# MKS22F12 register map
Vendor: Freescale Semiconductor, Inc.; Series: Kinetis_K; File version: 1.6
CPU: CM4 r0p1, little endian, no MPU, FPU, VTOR, 4 interrupt priority bits
Registers are 32-bit, read-write, reset 0x0 unless marked. A register's access mark holds for its fields unless they carry their own. Offsets are from the block's base; [hi:lo] are bit positions; {n}, {i} and the like mark numbered series; 'fields as' and 'values as' point back to an identical list.

## SIM — System Integration Module
Base 0x40047000; register names take the prefix SIM_
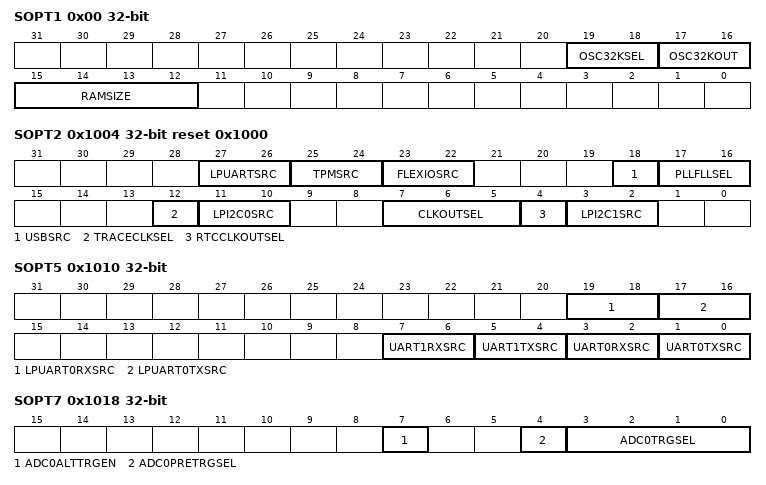
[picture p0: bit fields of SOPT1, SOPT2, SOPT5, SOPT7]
0x00 SOPT1 (reset mask 0x1FFF0FC0) — System Options Register 1
  [19:18] OSC32KSEL — 32K oscillator clock select
    0=System oscillator (OSC32KCLK); 2=RTC 32.768kHz oscillator; 3=LPO 1 kHz
  [17:16] OSC32KOUT — 32K Oscillator Clock Output
    0=ERCLK32K is not output; 1=ERCLK32K is output on PTE0; 2=ERCLK32K is output on PTE26
  [15:12] RAMSIZE ro
    1=8 KB; 3=16 KB; 4=24 KB; 5=32 KB; 6=48 KB; 7=64 KB; 8=96 KB; 9=128 KB; 11=256 KB
0x1004 SOPT2 reset 0x1000 — System Options Register 2
  [27:26] LPUARTSRC — LPUART clock source select
    0=Clock disabled; 1=MCGFLLCLK , or MCGPLLCLK , or IRC48M clock as selected by SOPT2[PLLFLLSEL]; 2=OSCERCLK clock; 3=MCGIRCLK clock
  [25:24] TPMSRC — TPM clock source select
    values as LPUARTSRC
  [23:22] FLEXIOSRC — FlexIO Module Clock Source Select
    0=I2S0_MCLK or System clock, selected via SIM_MISCCTRL[FlEXIOS0]; 1=MCGFLLCLK , or MCGPLLCLK , or IRC48M clock as selected by SOPT2[PLLFLLSEL]; 2=OSCERCLK clock; 3=MCGIRCLK clock
  [18] USBSRC — USB clock source select
    0=External bypass clock (USB_CLKIN); 1=MCGFLLCLK, or MCGPLLCLK , or IRC48M clock as selected by SOPT2[PLLFLLSEL], and then divided by the USB fractional divider as configured by SIM_CLKDIV2[USBFRAC, USBDIV]
  [17:16] PLLFLLSEL — PLL/FLL clock select
    0=MCGFLLCLK clock; 1=MCGPLLCLK clock; 3=IRC48 MHz clock
  [12] TRACECLKSEL — Debug trace clock select
    0=MCGOUTCLK; 1=Core/system clock
  [11:10] LPI2C0SRC — LPI2C0 source
    values as LPUARTSRC
  [7:5] CLKOUTSEL — CLKOUT select
    2=Flash clock; 3=LPO clock (1 kHz); 4=MCGIRCLK; 5=RTC 32.768kHz clock; 6=OSCERCLK0; 7=IRC 48 MHz clock
  [4] RTCCLKOUTSEL — RTC clock out select
    0=RTC 1 Hz clock is output on the RTC_CLKOUT pin; 1=RTC 32.768kHz clock is output on the RTC_CLKOUT pin
  [3:2] LPI2C1SRC — LPI2C1 source
    values as LPUARTSRC
0x1010 SOPT5 — System Options Register 5
  [19:18] LPUART0RXSRC — LPUART0 receive data source select
    0=LPUART0_RX pin; 1=CMP0 output
  [17:16] LPUART0TXSRC — LPUART0 transmit data source select
    0=LPUART0_TX pin; 1=LPUART0_TX pin modulated with TPM1 channel 0 output; 2=LPUART0_TX pin modulated with TPM2 channel 0 output
  [7:6] UART1RXSRC — UART 1 receive data source select
    0=UART1_RX pin; 1=CMP0 output
  [5:4] UART1TXSRC — UART 1 transmit data source select
    0=UART1_TX pin; 1=UART1_TX pin modulated with TPM1 channel 0 output; 2=UART1_TX pin modulated with TPM2 channel 0 output
  [3:2] UART0RXSRC — UART 0 receive data source select
    0=UART0_RX pin; 1=CMP0 output
  [1:0] UART0TXSRC — UART 0 transmit data source select
    0=UART0_TX pin; 1=UART0_TX pin modulated with TPM1 channel 0 output; 2=UART0_TX pin modulated with TPM2 channel 0 output
0x1018 SOPT7 — System Options Register 7
  [7] ADC0ALTTRGEN — ADC0 alternate trigger enable
    0=PDB trigger selected for ADC0; 1=Alternate trigger selected for ADC0
  [4] ADC0PRETRGSEL — ADC0 pretrigger select
    0=Pre-trigger A; 1=Pre-trigger B
  [3:0] ADC0TRGSEL — ADC0 trigger select
    0=PDB external trigger pin input (PDB0_EXTRG); 1=High speed comparator 0 output; {v}=PIT trigger {v-4} (v=4..7); 8=TPM0 overflow; 9=TPM1 overflow; 10=TPM2 overflow; 12=RTC alarm; 13=RTC seconds; 14=Low-power timer (LPTMR) trigger; 15=TPM1 channel 0 (A pretrigger) and channel 1 (B pretrigger)
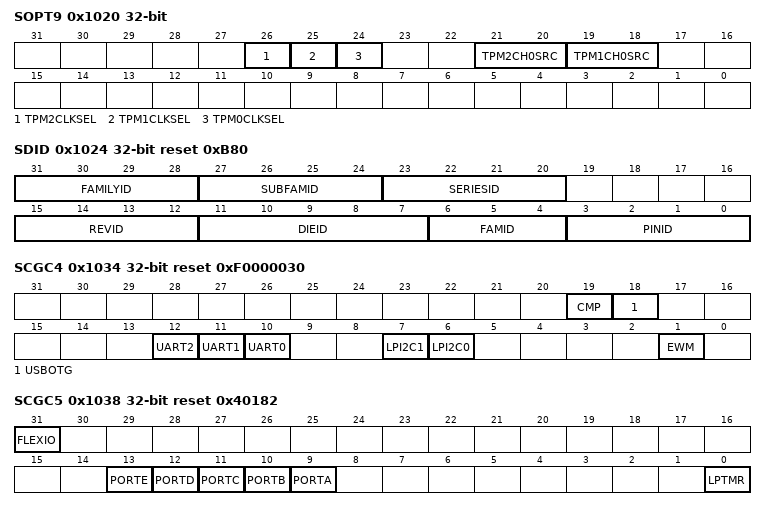
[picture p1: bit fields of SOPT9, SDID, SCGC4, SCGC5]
0x1020 SOPT9 — System Options Register 9
  [26] TPM2CLKSEL — TPM2 External Clock Pin Select
    0=TPM_CLKIN0 pin; 1=TPM_CLKIN1 pin
  [25] TPM1CLKSEL — TPM1 External Clock Pin Select
    0=TPM_CLKIN0 pin; 1=TPM_CLKIN1 pin
  [24] TPM0CLKSEL — TPM0 External Clock Pin Select
    0=TPM_CLKIN0 pin; 1=TPM_CLKIN1 pin
  [21:20] TPM2CH0SRC — TPM2 channel 0 input capture source select
    0=TPM2_CH0 signal; 1=CMP0 output
  [19:18] TPM1CH0SRC — TPM1 channel 0 input capture source select
    0=TPM1_CH0 signal; 1=CMP0 output; 3=USB start of frame pulse
0x1024 SDID ro reset 0xB80 (reset mask 0xF0F80) — System Device Identification Register
  [31:28] FAMILYID — Kinetis Family ID
    {v}=KS{v}x Family (v=0..9)
  [27:24] SUBFAMID — Kinetis Sub-Family ID
    0=KSx0 Subfamily; 2=KSx2 Subfamily; 4=KSx4 Subfamily; 6=KSx6 Subfamily; 7=KSx7 Subfamily
  [23:20] SERIESID — Kinetis Series ID
    0=Kinetis K series; 1=Kinetis L series; 5=Kinetis W series; 6=Kinetis V series; 7=Kinetis KS series
  [15:12] REVID — Device revision number
  [11:7] DIEID — Device Die ID
  [6:4] FAMID — Kinetis family identification
    0=KS0x or KS1x; {v}=KS{v+1}x (v=1..6); 7=KS8x or KS9x
  [3:0] PINID — Pincount identification
    2=32-pin; 4=48-pin; 5=64-pin; 6=80-pin; 7=81-pin or 121-pin; 8=100-pin; 9=121-pin; 10=144-pin; 11=Custom pinout (WLCSP); 12=169-pin; 14=256-pin
0x1034 SCGC4 reset 0xF0000030 — System Clock Gating Control Register 4
  [all] fields
    0=Clock disabled; 1=Clock enabled
  [19] CMP — Comparator Clock Gate Control
  [18] USBOTG — USB Clock Gate Control
  [12] UART2 — UART2 Clock Gate Control
  [11] UART1 — UART1 Clock Gate Control
  [10] UART0 — UART0 Clock Gate Control
  [7] LPI2C1 — LPI2C1 Clock Gate Control
  [6] LPI2C0 — LPI2C0 Clock Gate Control
  [1] EWM — EWM Clock Gate Control
0x1038 SCGC5 reset 0x40182 — System Clock Gating Control Register 5
  [31] FLEXIO — FlexIO Clock Gate Control
    0=Clock disabled; 1=Clock enabled
  [13] PORTE — Port E Clock Gate Control
    0=Clock disabled; 1=Clock enabled
  [12] PORTD — Port D Clock Gate Control
    0=Clock disabled; 1=Clock enabled
  [11] PORTC — Port C Clock Gate Control
    0=Clock disabled; 1=Clock enabled
  [10] PORTB — Port B Clock Gate Control
    0=Clock disabled; 1=Clock enabled
  [9] PORTA — Port A Clock Gate Control
    0=Clock disabled; 1=Clock enabled
  [0] LPTMR — Low Power Timer Access Control
    0=Access disabled; 1=Access enabled
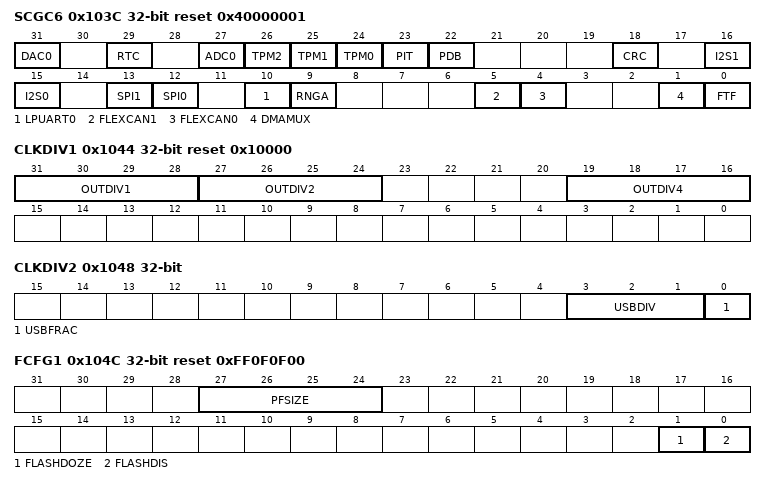
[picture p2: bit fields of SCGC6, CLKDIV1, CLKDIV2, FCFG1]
0x103C SCGC6 reset 0x40000001 — System Clock Gating Control Register 6
  [31] DAC0 — DAC0 Clock Gate Control
    0=Clock disabled; 1=Clock enabled
  [29] RTC — RTC Access Control
    0=Access and interrupts disabled; 1=Access and interrupts enabled
  [27] ADC0 — ADC0 Clock Gate Control
    0=Clock disabled; 1=Clock enabled
  [26] TPM2 — TPM2 Clock Gate Control
    0=Clock disabled; 1=Clock enabled
  [25] TPM1 — TPM1 Clock Gate Control
    0=Clock disabled; 1=Clock enabled
  [24] TPM0 — TPM0 Clock Gate Control
    0=Clock disabled; 1=Clock enabled
  [23] PIT — PIT Clock Gate Control
    0=Clock disabled; 1=Clock enabled
  [22] PDB — PDB Clock Gate Control
    0=Clock disabled; 1=Clock enabled
  [18] CRC — CRC Clock Gate Control
    0=Clock disabled; 1=Clock enabled
  [16] I2S1 — I2S1 Clock Gate Control
    0=Clock disabled; 1=Clock enabled
  [15] I2S0 — I2S0 Clock Gate Control
    0=Clock disabled; 1=Clock enabled
  [13] SPI1 — SPI1 Clock Gate Control
    0=Clock disabled; 1=Clock enabled
  [12] SPI0 — SPI0 Clock Gate Control
    0=Clock disabled; 1=Clock enabled
  [10] LPUART0 — LPUART0 Clock Gate Control
    0=Clock disabled; 1=Clock enabled
  [9] RNGA — RNGA Clock Gate Control
  [5] FLEXCAN1 — FlexCAN1 Clock Gate Control
    0=Clock disabled; 1=Clock enabled
  [4] FLEXCAN0 — FlexCAN0 Clock Gate Control
    0=Clock disabled; 1=Clock enabled
  [1] DMAMUX — DMA Mux Clock Gate Control
    0=Clock disabled; 1=Clock enabled
  [0] FTF — Flash Memory Clock Gate Control
    0=Clock disabled; 1=Clock enabled
0x1040 SCGC7 reset 0x2 — System Clock Gating Control Register 7
  [1] DMA — DMA Clock Gate Control
    0=Clock disabled; 1=Clock enabled
0x1044 CLKDIV1 reset 0x10000 — System Clock Divider Register 1
  [all] fields
    {v}=Divide-by-{v+1} (v=0..15)
  [31:28] OUTDIV1 — Clock 1 output divider value
  [27:24] OUTDIV2 — Clock 2 output divider value
  [19:16] OUTDIV4 — Clock 4 output divider value
0x1048 CLKDIV2 — System Clock Divider Register 2
  [3:1] USBDIV — USB clock divider divisor
  [0] USBFRAC — USB clock divider fraction
0x104C FCFG1 reset 0xFF0F0F00 — Flash Configuration Register 1
  [27:24] PFSIZE ro — Program flash size
    3=32 KB of program flash memory; 5=64 KB of program flash memory; 7=128 KB of program flash memory; 9=256 KB of program flash memory; 11=512 KB of program flash memory; 13=1024 KB of program flash memory; 15=256 KB of program flash memory
  [1] FLASHDOZE
    0=Flash remains enabled during Wait mode; 1=Flash is disabled for the duration of Wait mode
  [0] FLASHDIS — Flash Disable
    0=Flash is enabled; 1=Flash is disabled
0x1050 FCFG2 ro reset 0x20800000 — Flash Configuration Register 2
  [30:24] MAXADDR0 — Max address block 0
0x1054 UIDH ro — Unique Identification Register High
  [31:0] UID — Unique Identification
0x1058 UIDMH ro — Unique Identification Register Mid-High
  [31:0] UID — Unique Identification
0x105C UIDML ro — Unique Identification Register Mid Low
  [31:0] UID — Unique Identification
0x1060 UIDL ro — Unique Identification Register Low
  [31:0] UID — Unique Identification
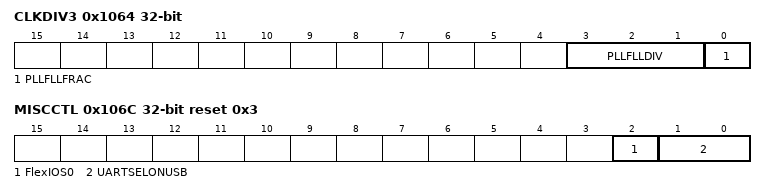
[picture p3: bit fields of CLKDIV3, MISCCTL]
0x1064 CLKDIV3 — System Clock Divider Register 3
  [3:1] PLLFLLDIV — PLLFLL clock divider divisor
  [0] PLLFLLFRAC — PLLFLL clock divider fraction
0x106C MISCCTL reset 0x3 — Miscellaneous Control Register
  [2] FlexIOS0 — FlexIO clock Slot 0 selection
    0=system clock; 1=I2S0_MCLK
  [1:0] UARTSELONUSB — UART Selection over USB DP/DM pins. For more details, see the "UART Over USB Capability" section in the USB chapter.
    0=UART0; 1=UART1; 2=UART2; 3=LPUART (default)

## Notices in the file
Redistribution and use in source and binary forms, with or without modification,
are permitted provided that the following conditions are met:
o Redistributions of source code must retain the above copyright notice, this list
of conditions and the following disclaimer.
o Redistributions in binary form must reproduce the above copyright notice, this
list of conditions and the following disclaimer in the documentation and/or
other materials provided with the distribution.
o Neither the name of Freescale Semiconductor, Inc. nor the names of its
contributors may be used to endorse or promote products derived from this
software without specific prior written permission.
THIS SOFTWARE IS PROVIDED BY THE COPYRIGHT HOLDERS AND CONTRIBUTORS "AS IS" AND
ANY EXPRESS OR IMPLIED WARRANTIES, INCLUDING, BUT NOT LIMITED TO, THE IMPLIED
WARRANTIES OF MERCHANTABILITY AND FITNESS FOR A PARTICULAR PURPOSE ARE
DISCLAIMED. IN NO EVENT SHALL THE COPYRIGHT HOLDER OR CONTRIBUTORS BE LIABLE FOR
ANY DIRECT, INDIRECT, INCIDENTAL, SPECIAL, EXEMPLARY, OR CONSEQUENTIAL DAMAGES
(INCLUDING, BUT NOT LIMITED TO, PROCUREMENT OF SUBSTITUTE GOODS OR SERVICES;
LOSS OF USE, DATA, OR PROFITS; OR BUSINESS INTERRUPTION) HOWEVER CAUSED AND ON
ANY THEORY OF LIABILITY, WHETHER IN CONTRACT, STRICT LIABILITY, OR TORT
(INCLUDING NEGLIGENCE OR OTHERWISE) ARISING IN ANY WAY OUT OF THE USE OF THIS
SOFTWARE, EVEN IF ADVISED OF THE POSSIBILITY OF SUCH DAMAGE.
